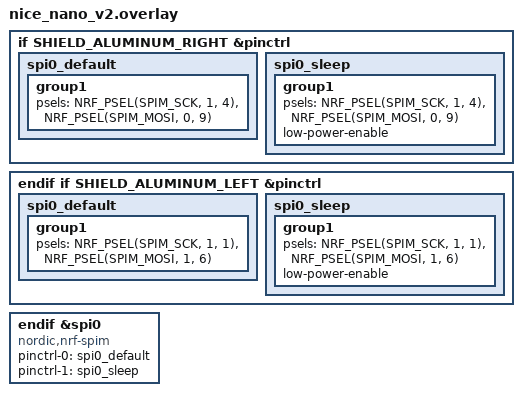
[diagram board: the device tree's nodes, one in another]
if SHIELD_ALUMINUM_RIGHT
/*Remember, right is the main half*/

&pinctrl {
    /* configuration for spi0 device, default state */
    spi0_default: spi0_default {
        /* node name is arbitrary */
        group1 {
            /* main role: configure P1.01 as SPI clock, P1.06 as SPI MOSI, don't use SPI MISO */
            psels = <NRF_PSEL(SPIM_SCK, 1, 4)>,
                    <NRF_PSEL(SPIM_MOSI, 0, 9)>;
        };
    };

    /* configuration for spi0 device, sleep state */
    spi0_sleep: spi0_sleep {
        group1 {
            /* main role: configure P1.01 as SPI clock, P1.06 as SPI MOSI, don't use SPI MISO */
            psels = <NRF_PSEL(SPIM_SCK, 1, 4)>,
                    <NRF_PSEL(SPIM_MOSI, 0, 9)>;
            low-power-enable;
        };
    };
};
endif

if SHIELD_ALUMINUM_LEFT

&pinctrl {
    /* configuration for spi0 device, default state */
    spi0_default: spi0_default {
        /* node name is arbitrary */
        group1 {
            /* main role: configure P1.01 as SPI clock, P1.06 as SPI MOSI, don't use SPI MISO */
            psels = <NRF_PSEL(SPIM_SCK, 1, 1)>,
                    <NRF_PSEL(SPIM_MOSI, 1, 6)>;
        };
    };

    /* configuration for spi0 device, sleep state */
    spi0_sleep: spi0_sleep {
        group1 {
            /* main role: configure P1.01 as SPI clock, P1.06 as SPI MOSI, don't use SPI MISO */
            psels = <NRF_PSEL(SPIM_SCK, 1, 1)>,
                    <NRF_PSEL(SPIM_MOSI, 1, 6)>;
            low-power-enable;
        };
    };
};
endif

&spi0 {
    compatible = "nordic,nrf-spim";
    pinctrl-0 = <&spi0_default>;
    pinctrl-1 = <&spi0_sleep>;
    pinctrl-names = "default", "sleep";
};
